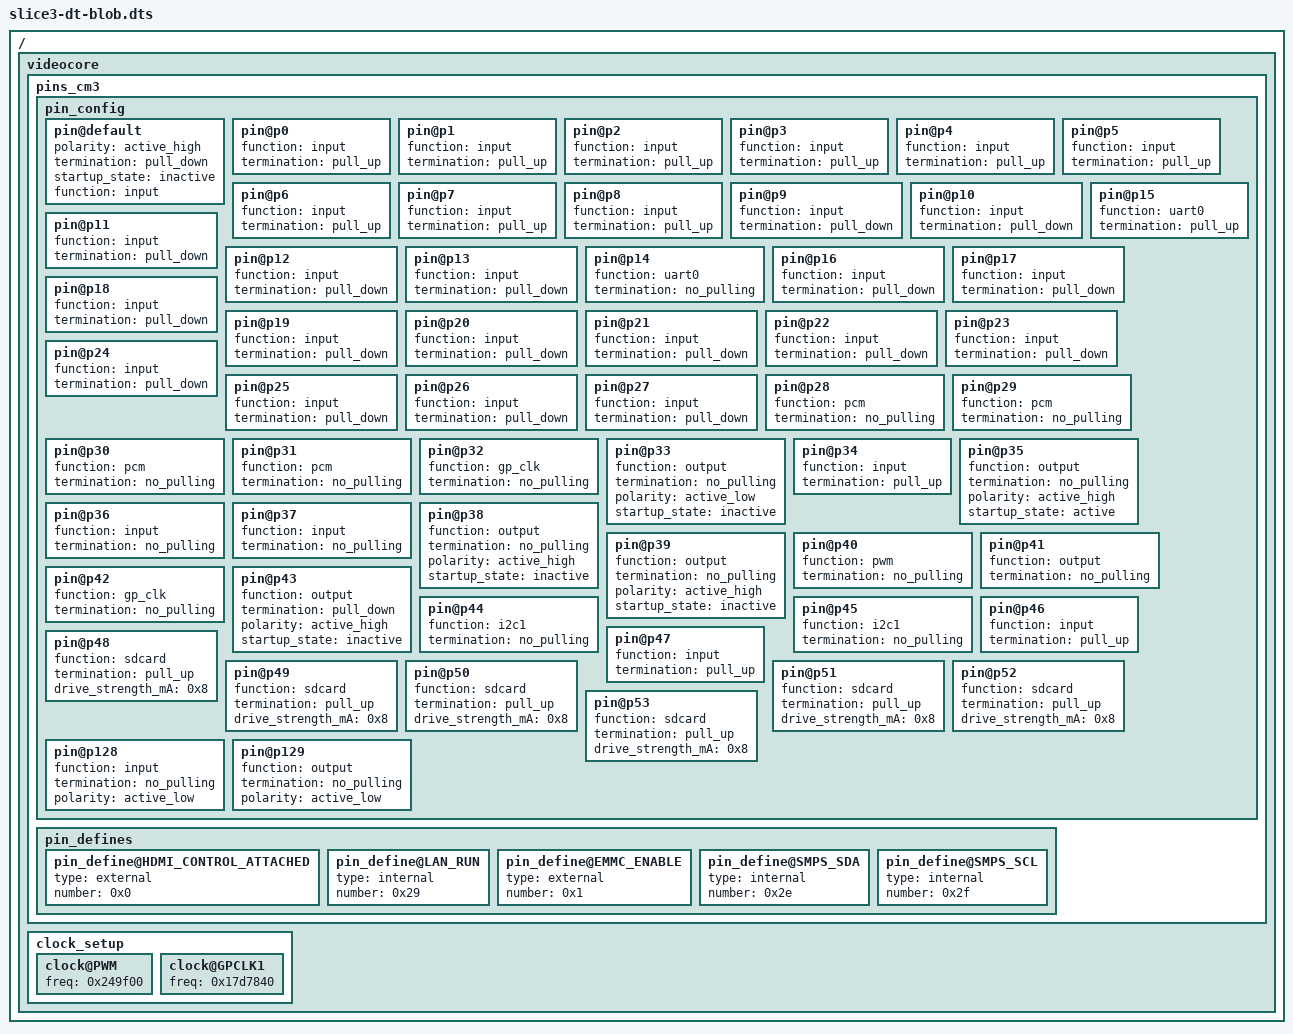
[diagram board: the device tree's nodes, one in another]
/dts-v1/;

/ {

	videocore {

		pins_cm3 {

			pin_config {

				pin@default {
					polarity = "active_high";
					termination = "pull_down";
					startup_state = "inactive";
					function = "input";
				};

				pin@p0 {
					function = "input";
					termination = "pull_up";
				};

				pin@p1 {
					function = "input";
					termination = "pull_up";
				};

				pin@p2 {
					function = "input";
					termination = "pull_up";
				};

				pin@p3 {
					function = "input";
					termination = "pull_up";
				};

				pin@p4 {
					function = "input";
					termination = "pull_up";
				};

				pin@p5 {
					function = "input";
					termination = "pull_up";
				};

				pin@p6 {
					function = "input";
					termination = "pull_up";
				};

				pin@p7 {
					function = "input";
					termination = "pull_up";
				};

				pin@p8 {
					function = "input";
					termination = "pull_up";
				};

				pin@p9 {
					function = "input";
					termination = "pull_down";
				};

				pin@p10 {
					function = "input";
					termination = "pull_down";
				};

				pin@p11 {
					function = "input";
					termination = "pull_down";
				};

				pin@p12 {
					function = "input";
					termination = "pull_down";
				};

				pin@p13 {
					function = "input";
					termination = "pull_down";
				};

				pin@p14 {
					function = "uart0";
					termination = "no_pulling";
				};

				pin@p15 {
					function = "uart0";
					termination = "pull_up";
				};

				pin@p16 {
					function = "input";
					termination = "pull_down";
				};

				pin@p17 {
					function = "input";
					termination = "pull_down";
				};

				pin@p18 {
					function = "input";
					termination = "pull_down";
				};

				pin@p19 {
					function = "input";
					termination = "pull_down";
				};

				pin@p20 {
					function = "input";
					termination = "pull_down";
				};

				pin@p21 {
					function = "input";
					termination = "pull_down";
				};

				pin@p22 {
					function = "input";
					termination = "pull_down";
				};

				pin@p23 {
					function = "input";
					termination = "pull_down";
				};

				pin@p24 {
					function = "input";
					termination = "pull_down";
				};

				pin@p25 {
					function = "input";
					termination = "pull_down";
				};

				pin@p26 {
					function = "input";
					termination = "pull_down";
				};

				pin@p27 {
					function = "input";
					termination = "pull_down";
				};

				pin@p28 {
					function = "pcm";
					termination = "no_pulling";
				};

				pin@p29 {
					function = "pcm";
					termination = "no_pulling";
				};

				pin@p30 {
					function = "pcm";
					termination = "no_pulling";
				};

				pin@p31 {
					function = "pcm";
					termination = "no_pulling";
				};

				pin@p32 {
					function = "gp_clk";
					termination = "no_pulling";
				};

				pin@p33 {
					function = "output";
					termination = "no_pulling";
					polarity = "active_low";
					startup_state = "inactive";
				};

				pin@p34 {
					function = "input";
					termination = "pull_up";
				};

				pin@p35 {
					function = "output";
					termination = "no_pulling";
					polarity = "active_high";
					startup_state = "active";
				};

				pin@p36 {
					function = "input";
					termination = "no_pulling";
				};

				pin@p37 {
					function = "input";
					termination = "no_pulling";
				};

				pin@p38 {
					function = "output";
					termination = "no_pulling";
					polarity = "active_high";
					startup_state = "inactive";
				};

				pin@p39 {
					function = "output";
					termination = "no_pulling";
					polarity = "active_high";
					startup_state = "inactive";
				};

				pin@p40 {
					function = "pwm";
					termination = "no_pulling";
				};

				pin@p41 {
					function = "output";
					termination = "no_pulling";
				};

				pin@p42 {
					function = "gp_clk";
					termination = "no_pulling";
				};

				pin@p43 {
					function = "output";
					termination = "pull_down";
					polarity = "active_high";
					startup_state = "inactive";
				};

				pin@p44 {
					function = "i2c1";
					termination = "no_pulling";
				};

				pin@p45 {
					function = "i2c1";
					termination = "no_pulling";
				};

				pin@p46 {
					function = "input";
					termination = "pull_up";
				};

				pin@p47 {
					function = "input";
					termination = "pull_up";
				};

				pin@p48 {
					function = "sdcard";
					termination = "pull_up";
					drive_strength_mA = <0x8>;
				};

				pin@p49 {
					function = "sdcard";
					termination = "pull_up";
					drive_strength_mA = <0x8>;
				};

				pin@p50 {
					function = "sdcard";
					termination = "pull_up";
					drive_strength_mA = <0x8>;
				};

				pin@p51 {
					function = "sdcard";
					termination = "pull_up";
					drive_strength_mA = <0x8>;
				};

				pin@p52 {
					function = "sdcard";
					termination = "pull_up";
					drive_strength_mA = <0x8>;
				};

				pin@p53 {
					function = "sdcard";
					termination = "pull_up";
					drive_strength_mA = <0x8>;
				};

				pin@p128 {
					function = "input";
					termination = "no_pulling";
					polarity = "active_low";
				};

				pin@p129 {
					function = "output";
					termination = "no_pulling";
					polarity = "active_low";
				};
			};

			pin_defines {

				pin_define@HDMI_CONTROL_ATTACHED {
					type = "external";
					number = <0x0>;
				};

				pin_define@LAN_RUN {
					type = "internal";
					number = <0x29>;
				};

				pin_define@EMMC_ENABLE {
					type = "external";
					number = <0x1>;
				};

				pin_define@SMPS_SDA {
					type = "internal";
					number = <0x2e>;
				};

				pin_define@SMPS_SCL {
					type = "internal";
					number = <0x2f>;
				};
			};
		};

		clock_setup {

			clock@PWM {
				freq = <0x249f00>;
			};

			clock@GPCLK1 {
				freq = <0x17d7840>;
			};
		};
	};
};
